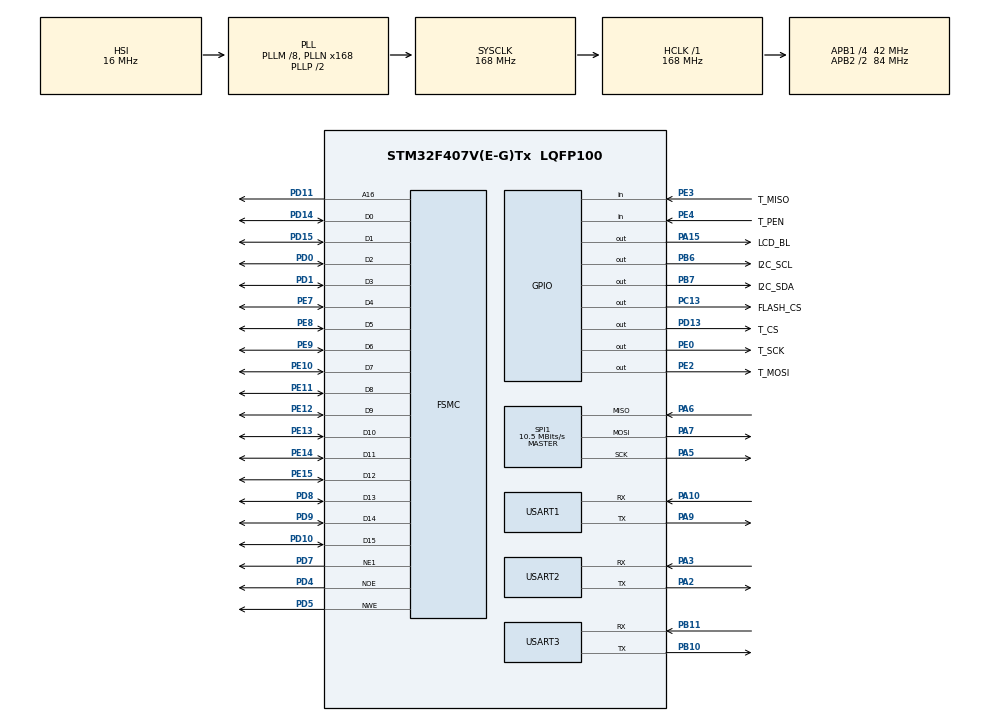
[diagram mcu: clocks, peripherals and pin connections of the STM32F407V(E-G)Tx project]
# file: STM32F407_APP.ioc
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Dma.Request0=USART1_RX
Dma.Request1=USART1_TX
Dma.Request2=USART3_RX
Dma.Request3=USART3_TX
Dma.Request4=USART2_RX
Dma.Request5=USART2_TX
Dma.USART1_RX.0.Direction=DMA_PERIPH_TO_MEMORY
Dma.USART1_RX.0.FIFOMode=DMA_FIFOMODE_DISABLE
Dma.USART1_RX.0.Instance=DMA2_Stream2
Dma.USART1_RX.0.MemDataAlignment=DMA_MDATAALIGN_BYTE
Dma.USART1_RX.0.MemInc=DMA_MINC_ENABLE
Dma.USART1_RX.0.Mode=DMA_CIRCULAR
Dma.USART1_RX.0.PeriphDataAlignment=DMA_PDATAALIGN_BYTE
Dma.USART1_RX.0.PeriphInc=DMA_PINC_DISABLE
Dma.USART1_RX.0.Priority=DMA_PRIORITY_MEDIUM
Dma.USART1_TX.1.Direction=DMA_MEMORY_TO_PERIPH
Dma.USART1_TX.1.FIFOMode=DMA_FIFOMODE_DISABLE
Dma.USART1_TX.1.Instance=DMA2_Stream7
Dma.USART1_TX.1.MemDataAlignment=DMA_MDATAALIGN_BYTE
Dma.USART1_TX.1.MemInc=DMA_MINC_ENABLE
Dma.USART1_TX.1.Mode=DMA_NORMAL
Dma.USART1_TX.1.PeriphDataAlignment=DMA_PDATAALIGN_BYTE
Dma.USART1_TX.1.PeriphInc=DMA_PINC_DISABLE
Dma.USART1_TX.1.Priority=DMA_PRIORITY_MEDIUM
Dma.USART2_RX.4.Direction=DMA_PERIPH_TO_MEMORY
Dma.USART2_RX.4.FIFOMode=DMA_FIFOMODE_DISABLE
Dma.USART2_RX.4.Instance=DMA1_Stream5
Dma.USART2_RX.4.MemDataAlignment=DMA_MDATAALIGN_BYTE
Dma.USART2_RX.4.MemInc=DMA_MINC_ENABLE
Dma.USART2_RX.4.Mode=DMA_CIRCULAR
Dma.USART2_RX.4.PeriphDataAlignment=DMA_PDATAALIGN_BYTE
Dma.USART2_RX.4.PeriphInc=DMA_PINC_DISABLE
Dma.USART2_RX.4.Priority=DMA_PRIORITY_MEDIUM
Dma.USART2_TX.5.Direction=DMA_MEMORY_TO_PERIPH
Dma.USART2_TX.5.FIFOMode=DMA_FIFOMODE_DISABLE
Dma.USART2_TX.5.Instance=DMA1_Stream6
Dma.USART2_TX.5.MemDataAlignment=DMA_MDATAALIGN_BYTE
Dma.USART2_TX.5.MemInc=DMA_MINC_ENABLE
Dma.USART2_TX.5.Mode=DMA_NORMAL
Dma.USART2_TX.5.PeriphDataAlignment=DMA_PDATAALIGN_BYTE
Dma.USART2_TX.5.PeriphInc=DMA_PINC_DISABLE
Dma.USART2_TX.5.Priority=DMA_PRIORITY_MEDIUM
Dma.USART3_RX.2.Direction=DMA_PERIPH_TO_MEMORY
Dma.USART3_RX.2.FIFOMode=DMA_FIFOMODE_DISABLE
Dma.USART3_RX.2.Instance=DMA1_Stream1
Dma.USART3_RX.2.MemDataAlignment=DMA_MDATAALIGN_BYTE
Dma.USART3_RX.2.MemInc=DMA_MINC_ENABLE
Dma.USART3_RX.2.Mode=DMA_CIRCULAR
Dma.USART3_RX.2.PeriphDataAlignment=DMA_PDATAALIGN_BYTE
Dma.USART3_RX.2.PeriphInc=DMA_PINC_DISABLE
Dma.USART3_RX.2.Priority=DMA_PRIORITY_MEDIUM
Dma.USART3_TX.3.Direction=DMA_MEMORY_TO_PERIPH
Dma.USART3_TX.3.FIFOMode=DMA_FIFOMODE_DISABLE
Dma.USART3_TX.3.Instance=DMA1_Stream3
Dma.USART3_TX.3.MemDataAlignment=DMA_MDATAALIGN_BYTE
Dma.USART3_TX.3.MemInc=DMA_MINC_ENABLE
Dma.USART3_TX.3.Mode=DMA_NORMAL
Dma.USART3_TX.3.PeriphDataAlignment=DMA_PDATAALIGN_BYTE
Dma.USART3_TX.3.PeriphInc=DMA_PINC_DISABLE
Dma.USART3_TX.3.Priority=DMA_PRIORITY_MEDIUM
FREERTOS.Tasks01=defaultTask,24,128,StartDefaultTask,Default,NULL,Dynamic,NULL,NULL
FSMC.AddressSetupTime1=2
FSMC.BusTurnAroundDuration1=0
FSMC.DataSetupTime1=25
FSMC.ExtendedAddressSetupTime1=2
FSMC.ExtendedBusTurnAroundDuration1=0
FSMC.ExtendedDataSetupTime1=8
FSMC.ExtendedMode1=FSMC_EXTENDED_MODE_ENABLE
Mcu.Family=STM32F4
Mcu.Name=STM32F407V(E-G)Tx
Mcu.Package=LQFP100
NVIC.DMA1_Stream1_IRQn=true\:5\:0\:false\:false\:true\:true\:false\:true\:true
NVIC.DMA1_Stream3_IRQn=true\:5\:0\:false\:false\:true\:true\:false\:true\:true
NVIC.DMA1_Stream5_IRQn=true\:5\:0\:false\:false\:true\:true\:false\:true\:true
NVIC.DMA1_Stream6_IRQn=true\:5\:0\:false\:false\:true\:true\:false\:true\:true
NVIC.DMA2_Stream2_IRQn=true\:5\:0\:false\:false\:true\:true\:false\:true\:true
NVIC.DMA2_Stream7_IRQn=true\:5\:0\:false\:false\:true\:true\:false\:true\:true
NVIC.PriorityGroup=NVIC_PRIORITYGROUP_4
NVIC.TIM2_IRQn=true\:15\:0\:false\:false\:true\:false\:false\:true\:true
NVIC.TimeBase=TIM2_IRQn
NVIC.TimeBaseIP=TIM2
NVIC.USART1_IRQn=true\:5\:0\:false\:false\:true\:true\:true\:true\:true
NVIC.USART2_IRQn=true\:5\:0\:false\:false\:true\:true\:true\:true\:true
NVIC.USART3_IRQn=true\:5\:0\:false\:false\:true\:true\:true\:true\:true
PA10.Mode=Asynchronous
PA10.Signal=USART1_RX
PA13.Mode=Serial_Wire
PA13.Signal=SYS_JTMS-SWDIO
PA14.Mode=Serial_Wire
PA14.Signal=SYS_JTCK-SWCLK
PA15.GPIO_Label=LCD_BL
PA15.Signal=GPIO_Output
PA2.Mode=Asynchronous
PA2.Signal=USART2_TX
PA3.Mode=Asynchronous
PA3.Signal=USART2_RX
PA5.Mode=Full_Duplex_Master
PA5.Signal=SPI1_SCK
PA6.Mode=Full_Duplex_Master
PA6.Signal=SPI1_MISO
PA7.Mode=Full_Duplex_Master
PA7.Signal=SPI1_MOSI
PA9.Mode=Asynchronous
PA9.Signal=USART1_TX
PB10.Mode=Asynchronous
PB10.Signal=USART3_TX
PB11.Mode=Asynchronous
PB11.Signal=USART3_RX
PB6.GPIO_Label=I2C_SCL
PB6.GPIO_ModeDefaultOutputPP=GPIO_MODE_OUTPUT_OD
PB6.GPIO_PuPd=GPIO_NOPULL
PB6.PinState=GPIO_PIN_SET
PB6.Signal=GPIO_Output
PB7.GPIO_Label=I2C_SDA
PB7.GPIO_ModeDefaultOutputPP=GPIO_MODE_OUTPUT_OD
PB7.GPIO_PuPd=GPIO_NOPULL
PB7.PinState=GPIO_PIN_SET
PB7.Signal=GPIO_Output
PC13-ANTI_TAMP.GPIO_Label=FLASH_CS
PC13-ANTI_TAMP.PinState=GPIO_PIN_SET
PC13-ANTI_TAMP.Signal=GPIO_Output
PC14-OSC32_IN.Mode=LSE-External-Oscillator
PC14-OSC32_IN.Signal=RCC_OSC32_IN
PC15-OSC32_OUT.Mode=LSE-External-Oscillator
PC15-OSC32_OUT.Signal=RCC_OSC32_OUT
PD0.Mode=16b-d1
PD0.Signal=FSMC_D2
PD1.Mode=16b-d1
PD1.Signal=FSMC_D3
PD10.Mode=16b-d1
PD10.Signal=FSMC_D15
PD11.Mode=A16_1
PD11.Signal=FSMC_A16
PD13.GPIO_Label=T_CS
PD13.PinState=GPIO_PIN_SET
PD13.Signal=GPIO_Output
PD14.Mode=16b-d1
PD14.Signal=FSMC_D0
PD15.Mode=16b-d1
PD15.Signal=FSMC_D1
PD4.Mode=Lcd1
PD4.Signal=FSMC_NOE
PD5.Mode=Lcd1
PD5.Signal=FSMC_NWE
PD7.Mode=NorPsramChipSelect1_1
PD7.Signal=FSMC_NE1
PD8.Mode=16b-d1
PD8.Signal=FSMC_D13
PD9.Mode=16b-d1
PD9.Signal=FSMC_D14
PE0.GPIO_Label=T_SCK
PE0.Signal=GPIO_Output
PE10.Mode=16b-d1
PE10.Signal=FSMC_D7
PE11.Mode=16b-d1
PE11.Signal=FSMC_D8
PE12.Mode=16b-d1
PE12.Signal=FSMC_D9
PE13.Mode=16b-d1
PE13.Signal=FSMC_D10
PE14.Mode=16b-d1
PE14.Signal=FSMC_D11
PE15.Mode=16b-d1
PE15.Signal=FSMC_D12
PE2.GPIO_Label=T_MOSI
PE2.Signal=GPIO_Output
PE3.GPIO_Label=T_MISO
PE3.Signal=GPIO_Input
PE4.GPIO_Label=T_PEN
PE4.Signal=GPIO_Input
PE7.Mode=16b-d1
PE7.Signal=FSMC_D4
PE8.Mode=16b-d1
PE8.Signal=FSMC_D5
PE9.Mode=16b-d1
PE9.Signal=FSMC_D6
PH0-OSC_IN.Mode=HSE-External-Oscillator
PH0-OSC_IN.Signal=RCC_OSC_IN
PH1-OSC_OUT.Mode=HSE-External-Oscillator
PH1-OSC_OUT.Signal=RCC_OSC_OUT
ProjectManager.HeapSize=0x200
ProjectManager.StackSize=0x400
ProjectManager.TargetToolchain=MDK-ARM V5.32
RCC.48MHZClocksFreq_Value=84000000
RCC.AHBFreq_Value=168000000
RCC.APB1CLKDivider=RCC_HCLK_DIV4
RCC.APB1Freq_Value=42000000
RCC.APB1TimFreq_Value=84000000
RCC.APB2CLKDivider=RCC_HCLK_DIV2
RCC.APB2Freq_Value=84000000
RCC.APB2TimFreq_Value=168000000
RCC.CortexFreq_Value=168000000
RCC.HCLKFreq_Value=168000000
RCC.HSE_VALUE=25000000
RCC.HSI_VALUE=16000000
RCC.PLLM=8
RCC.PLLN=168
RCC.SYSCLKFreq_VALUE=168000000
RCC.SYSCLKSource=RCC_SYSCLKSOURCE_PLLCLK
RCC.VCOOutputFreq_Value=336000000
SPI1.BaudRatePrescaler=SPI_BAUDRATEPRESCALER_8
SPI1.CalculateBaudRate=10.5 MBits/s
SPI1.Direction=SPI_DIRECTION_2LINES
SPI1.Mode=SPI_MODE_MASTER
SPI1.VirtualType=VM_MASTER
USART1.VirtualMode=VM_ASYNC
USART2.VirtualMode=VM_ASYNC
USART3.VirtualMode=VM_ASYNC
VP_FREERTOS_VS_CMSIS_V2.Mode=CMSIS_V2
VP_SYS_VS_tim2.Mode=TIM2
board=custom

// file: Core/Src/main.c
/* USER CODE BEGIN Header */
/**
  ******************************************************************************
  * @file           : main.c
  * @brief          : Main program body
  ******************************************************************************
  * @attention
  *
  * Copyright (c) 2026 STMicroelectronics.
  * All rights reserved.
  *
  * This software is licensed under terms that can be found in the LICENSE file
  * in the root directory of this software component.
  * If no LICENSE file comes with this software, it is provided AS-IS.
  *
  ******************************************************************************
  */
/* USER CODE END Header */
#include "main.h"
#include "cmsis_os.h"
#include "dma.h"
#include "spi.h"
#include "usart.h"
#include "gpio.h"
#include "fsmc.h"

void SystemClock_Config(void);
void MX_FREERTOS_Init(void);

int main(void)
{

  /* MCU Configuration--------------------------------------------------------*/

  /* Reset of all peripherals, Initializes the Flash interface and the Systick. */
  HAL_Init();

  /* Configure the system clock */
  SystemClock_Config();

  /* Initialize all configured peripherals */
  MX_GPIO_Init();
  MX_DMA_Init();
  MX_USART1_UART_Init();
  MX_USART3_UART_Init();
  MX_USART2_UART_Init();
  MX_SPI1_Init();
  MX_FSMC_Init();

  /* Init scheduler */
  osKernelInitialize();  /* Call init function for freertos objects (in freertos.c) */
  MX_FREERTOS_Init();

  /* Start scheduler */
  osKernelStart();
  /* We should never get here as control is now taken by the scheduler */
  /* Infinite loop */
  while (1)
  {

  }
}

void SystemClock_Config(void)
{
  RCC_OscInitTypeDef RCC_OscInitStruct = {0};
  RCC_ClkInitTypeDef RCC_ClkInitStruct = {0};

  /** Configure the main internal regulator output voltage
  */
  __HAL_RCC_PWR_CLK_ENABLE();
  __HAL_PWR_VOLTAGESCALING_CONFIG(PWR_REGULATOR_VOLTAGE_SCALE1);

  /** Initializes the RCC Oscillators according to the specified parameters
  * in the RCC_OscInitTypeDef structure.
  */
  RCC_OscInitStruct.OscillatorType = RCC_OSCILLATORTYPE_HSI;
  RCC_OscInitStruct.HSIState = RCC_HSI_ON;
  RCC_OscInitStruct.HSICalibrationValue = RCC_HSICALIBRATION_DEFAULT;
  RCC_OscInitStruct.PLL.PLLState = RCC_PLL_ON;
  RCC_OscInitStruct.PLL.PLLSource = RCC_PLLSOURCE_HSI;
  RCC_OscInitStruct.PLL.PLLM = 8;
  RCC_OscInitStruct.PLL.PLLN = 168;
  RCC_OscInitStruct.PLL.PLLP = RCC_PLLP_DIV2;
  RCC_OscInitStruct.PLL.PLLQ = 4;
  if (HAL_RCC_OscConfig(&RCC_OscInitStruct) != HAL_OK)
  {
    Error_Handler();
  }

  /** Initializes the CPU, AHB and APB buses clocks
  */
  RCC_ClkInitStruct.ClockType = RCC_CLOCKTYPE_HCLK|RCC_CLOCKTYPE_SYSCLK
                              |RCC_CLOCKTYPE_PCLK1|RCC_CLOCKTYPE_PCLK2;
  RCC_ClkInitStruct.SYSCLKSource = RCC_SYSCLKSOURCE_PLLCLK;
  RCC_ClkInitStruct.AHBCLKDivider = RCC_SYSCLK_DIV1;
  RCC_ClkInitStruct.APB1CLKDivider = RCC_HCLK_DIV4;
  RCC_ClkInitStruct.APB2CLKDivider = RCC_HCLK_DIV2;

  if (HAL_RCC_ClockConfig(&RCC_ClkInitStruct, FLASH_LATENCY_5) != HAL_OK)
  {
    Error_Handler();
  }
}

void HAL_TIM_PeriodElapsedCallback(TIM_HandleTypeDef *htim)
{
  if (htim->Instance == TIM2) {
    HAL_IncTick();
  }
}

void Error_Handler(void)
{
  __disable_irq();
  while (1)
  {
  }
}

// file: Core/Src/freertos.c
/* USER CODE BEGIN Header */
/**
  ******************************************************************************
  * File Name          : freertos.c
  * Description        : Code for freertos applications
  ******************************************************************************
  * @attention
  *
  * Copyright (c) 2026 STMicroelectronics.
  * All rights reserved.
  *
  * This software is licensed under terms that can be found in the LICENSE file
  * in the root directory of this software component.
  * If no LICENSE file comes with this software, it is provided AS-IS.
  *
  ******************************************************************************
  */
/* USER CODE END Header */

#include "FreeRTOS.h"
#include "task.h"
#include "main.h"
#include "cmsis_os.h"

/* USER CODE BEGIN Includes */
#include "cmbacktrace_port.h"
#include "diagnostics_fault.h"
#include "service_log.h"

/* USER CODE END Includes */

/* Definitions for defaultTask */
osThreadId_t defaultTaskHandle;
const osThreadAttr_t defaultTask_attributes = {
  .name = "defaultTask",
  .stack_size = 128 * 4,
  .priority = (osPriority_t) osPriorityNormal,
};

void StartDefaultTask(void *argument);

void MX_FREERTOS_Init(void); /* (MISRA C 2004 rule 8.1) */

void MX_FREERTOS_Init(void) {
  /* USER CODE BEGIN Init */
  platform_error_t service_log_init_result = service_log_init();
  cmbacktrace_port_init();
  diagnostics_fault_init();
  if (service_log_init_result != PLATFORM_ERR_OK)
  {
    Error_Handler();
  }

  /* USER CODE END Init */

  /* Create the thread(s) */
  /* creation of defaultTask */
  defaultTaskHandle = osThreadNew(StartDefaultTask, NULL, &defaultTask_attributes);

}

void StartDefaultTask(void *argument)
{
  for(;;)
  {
    osDelay(1);
  }
}
